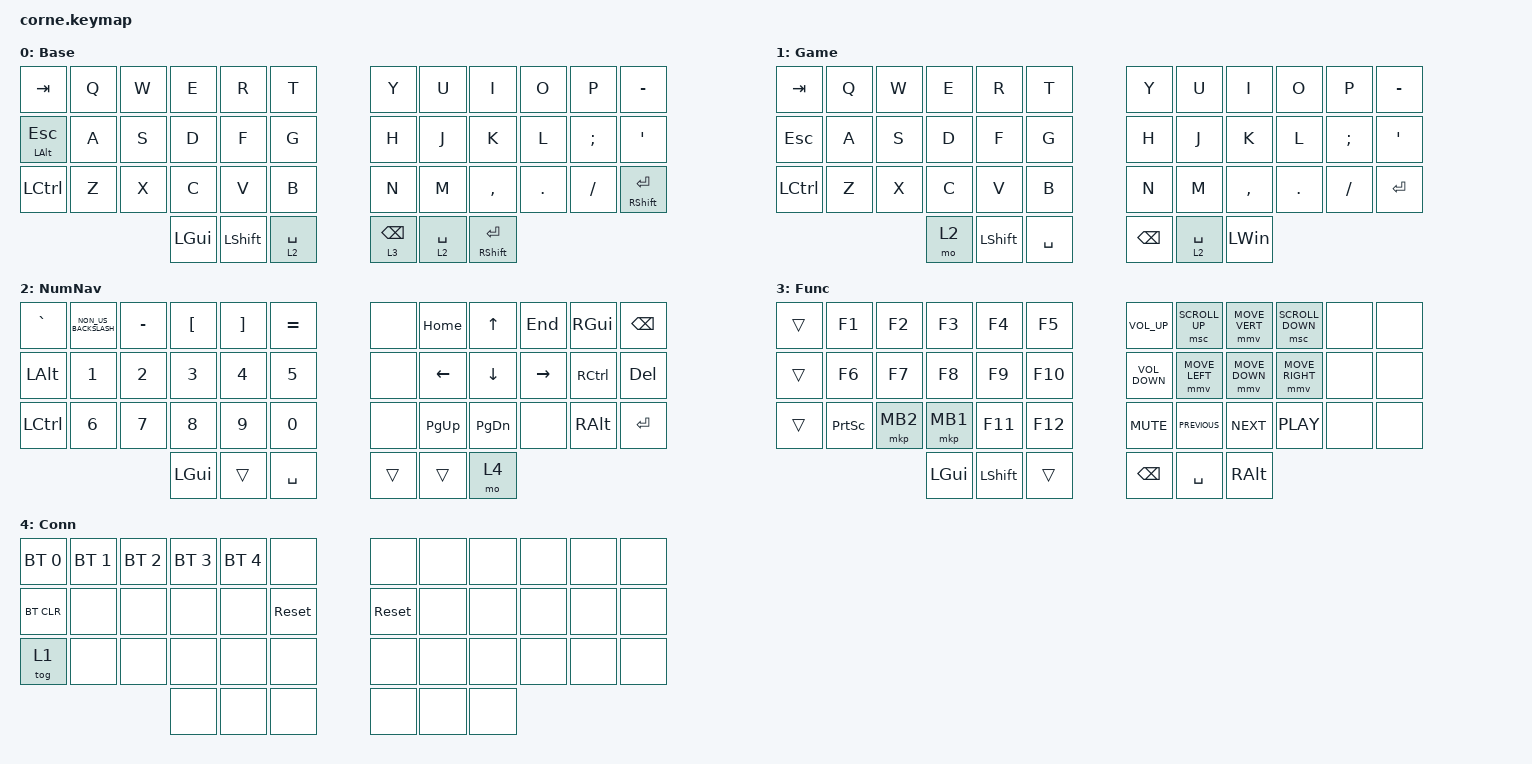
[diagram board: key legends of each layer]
/*
 * Copyright (c) 2020 The ZMK Contributors
 *
 * SPDX-License-Identifier: MIT
 */

#include <behaviors.dtsi>
#include <dt-bindings/zmk/bt.h>
#include <dt-bindings/zmk/keys.h>
#include <dt-bindings/zmk/mouse.h>

&lt { quick-tap-ms = <150>; };

&mt { quick-tap-ms = <150>; };

/ {
    combos {
        compatible = "zmk,combos";

        mid-mouse {
            bindings = <&mkp MB3>;
            key-positions = <7 9>;
            layers = <3>;
        };

        mb3 {
            bindings = <&mkp MB3>;
            key-positions = <26 27>;
            layers = <3>;
        };
    };

    keymap {
        compatible = "zmk,keymap";

        default_layer {
            // -----------------------------------------------------------------------------------------
            // |  TAB |  Q  |  W  |  E  |  R  |  T  |   |  Y  |  U   |  I  |  O  |  P  | BKSP |
            // | CTRL |  A  |  S  |  D  |  F  |  G  |   |  H  |  J   |  K  |  L  |  ;  |  '   |
            // | SHFT |  Z  |  X  |  C  |  V  |  B  |   |  N  |  M   |  ,  |  .  |  /  | ESC  |
            //                    | GUI | LWR | SPC |   | ENT | RSE  | ALT |

            display-name = "Base";
            bindings = <
&kp TAB              &kp Q  &kp W  &kp E     &kp R           &kp T          &kp Y            &kp U        &kp I             &kp O    &kp P     &kp MINUS
&mt LEFT_ALT ESCAPE  &kp A  &kp S  &kp D     &kp F           &kp G          &kp H            &kp J        &kp K             &kp L    &kp SEMI  &kp SQT
&kp LCTRL            &kp Z  &kp X  &kp C     &kp V           &kp B          &kp N            &kp M        &kp COMMA         &kp DOT  &kp FSLH  &mt RIGHT_SHIFT ENTER
                                   &kp LGUI  &kp LEFT_SHIFT  &lt 2 SPACE    &lt 3 BACKSPACE  &lt 2 SPACE  &mt RSHIFT ENTER
            >;
        };

        gaming {
            bindings = <
&kp TAB    &kp Q  &kp W  &kp E  &kp R      &kp T        &kp Y          &kp U        &kp I         &kp O    &kp P     &kp MINUS
&kp ESC    &kp A  &kp S  &kp D  &kp F      &kp G        &kp H          &kp J        &kp K         &kp L    &kp SEMI  &kp APOS
&kp LCTRL  &kp Z  &kp X  &kp C  &kp V      &kp B        &kp N          &kp M        &kp COMMA     &kp DOT  &kp FSLH  &kp ENTER
                         &mo 2  &kp LSHFT  &kp SPACE    &kp BACKSPACE  &lt 2 SPACE  &kp LEFT_WIN
            >;

            label = "Game";
        };

        num_nav {
            // -----------------------------------------------------------------------------------------
            // |  TAB |  1  |  2  |  3  |  4  |  5  |   |  6  |  7  |  8  |  9  |  0  | BKSP |
            // | BTCLR| BT1 | BT2 | BT3 | BT4 | BT5 |   | LFT | DWN |  UP | RGT |     |      |
            // | SHFT |     |     |     |     |     |   |     |     |     |     |     |      |
            //                    | GUI |     | SPC |   | ENT |     | ALT |

            display-name = "NumNav";
            bindings = <
&kp GRAVE  &kp NON_US_BACKSLASH  &kp MINUS  &kp LBKT  &kp RBKT  &kp EQUAL    &none   &kp HOME     &kp UP_ARROW   &kp END    &kp RIGHT_GUI      &kp BSPC
&kp LALT   &kp N1                &kp N2     &kp N3    &kp N4    &kp N5       &none   &kp LEFT     &kp DOWN       &kp RIGHT  &kp RIGHT_CONTROL  &kp DELETE
&kp LCTRL  &kp N6                &kp N7     &kp N8    &kp N9    &kp N0       &none   &kp PAGE_UP  &kp PAGE_DOWN  &none      &kp RALT           &kp ENTER
                                            &kp LGUI  &trans    &kp SPACE    &trans  &trans       &mo 4
            >;
        };

        function {
            // -----------------------------------------------------------------------------------------
            // |  TAB |  !  |  @  |  #  |  $  |  %  |   |  ^  |  &  |  *  |  (  |  )  | BKSP |
            // | CTRL |     |     |     |     |     |   |  -  |  =  |  [  |  ]  |  \  |  `   |
            // | SHFT |     |     |     |     |     |   |  _  |  +  |  {  |  }  | "|" |  ~   |
            //                    | GUI |     | SPC |   | ENT |     | ALT |

            display-name = "Func";
            bindings = <
&trans  &kp F1           &kp F2    &kp F3    &kp F4          &kp F5     &kp C_VOLUME_UP    &msc SCROLL_UP  &mmv MOVE_VERT 200  &msc SCROLL_DOWN  &none  &none
&trans  &kp F6           &kp F7    &kp F8    &kp F9          &kp F10    &kp C_VOLUME_DOWN  &mmv MOVE_LEFT  &mmv MOVE_DOWN      &mmv MOVE_RIGHT   &none  &none
&trans  &kp PRINTSCREEN  &mkp MB2  &mkp MB1  &kp F11         &kp F12    &kp C_MUTE         &kp C_PREVIOUS  &kp C_NEXT          &kp C_PLAY        &none  &none
                                   &kp LGUI  &kp LEFT_SHIFT  &trans     &kp BACKSPACE      &kp SPACE       &kp RALT
            >;
        };

        connect {
            bindings = <
&bt BT_SEL 0  &bt BT_SEL 1  &bt BT_SEL 2  &bt BT_SEL 3  &bt BT_SEL 4  &none         &none       &none  &none  &none  &none  &none
&bt BT_CLR    &none         &none         &none         &none         &sys_reset    &sys_reset  &none  &none  &none  &none  &none
&tog 1        &none         &none         &none         &none         &none         &none       &none  &none  &none  &none  &none
                                          &none         &none         &none         &none       &none  &none
            >;

            label = "Conn";
        };
    };
};
